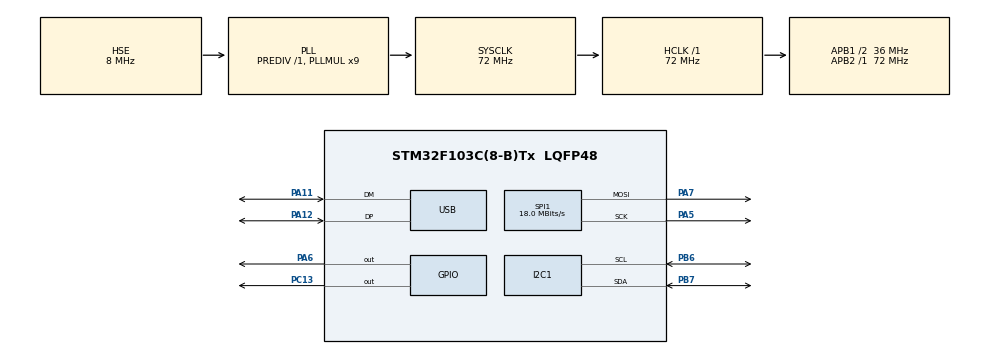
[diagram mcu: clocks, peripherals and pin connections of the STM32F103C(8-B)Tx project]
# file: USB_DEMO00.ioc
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Mcu.Family=STM32F1
Mcu.Name=STM32F103C(8-B)Tx
Mcu.Package=LQFP48
NVIC.PriorityGroup=NVIC_PRIORITYGROUP_4
NVIC.USB_LP_CAN1_RX0_IRQn=true\:0\:0\:false\:false\:true\:false\:true\:true
PA11.Mode=Device
PA11.Signal=USB_DM
PA12.Mode=Device
PA12.Signal=USB_DP
PA13.Mode=Serial_Wire
PA13.Signal=SYS_JTMS-SWDIO
PA14.Mode=Serial_Wire
PA14.Signal=SYS_JTCK-SWCLK
PA5.Mode=TX_Only_Simplex_Unidirect_Master
PA5.Signal=SPI1_SCK
PA6.Signal=GPIO_Output
PA7.Mode=TX_Only_Simplex_Unidirect_Master
PA7.Signal=SPI1_MOSI
PB6.Mode=I2C
PB6.Signal=I2C1_SCL
PB7.Mode=I2C
PB7.Signal=I2C1_SDA
PC13-TAMPER-RTC.Signal=GPIO_Output
PC14-OSC32_IN.Mode=LSE-External-Oscillator
PC14-OSC32_IN.Signal=RCC_OSC32_IN
PC15-OSC32_OUT.Mode=LSE-External-Oscillator
PC15-OSC32_OUT.Signal=RCC_OSC32_OUT
PD0-OSC_IN.Mode=HSE-External-Oscillator
PD0-OSC_IN.Signal=RCC_OSC_IN
PD1-OSC_OUT.Mode=HSE-External-Oscillator
PD1-OSC_OUT.Signal=RCC_OSC_OUT
ProjectManager.HeapSize=0x200
ProjectManager.StackSize=0x400
ProjectManager.TargetToolchain=CMake
RCC.AHBFreq_Value=72000000
RCC.APB1CLKDivider=RCC_HCLK_DIV2
RCC.APB1Freq_Value=36000000
RCC.APB1TimFreq_Value=72000000
RCC.APB2Freq_Value=72000000
RCC.APB2TimFreq_Value=72000000
RCC.HCLKFreq_Value=72000000
RCC.PLLMUL=RCC_PLL_MUL9
RCC.SYSCLKFreq_VALUE=72000000
RCC.SYSCLKSource=RCC_SYSCLKSOURCE_PLLCLK
RCC.USBFreq_Value=48000000
RCC.USBPrescaler=RCC_USBCLKSOURCE_PLL_DIV1_5
SPI1.BaudRatePrescaler=SPI_BAUDRATEPRESCALER_4
SPI1.CalculateBaudRate=18.0 MBits/s
SPI1.Direction=SPI_DIRECTION_2LINES
SPI1.Mode=SPI_MODE_MASTER
SPI1.VirtualType=VM_MASTER
USB_DEVICE.CLASS_NAME_FS=CDC
USB_DEVICE.VirtualMode=Cdc
USB_DEVICE.VirtualModeFS=Cdc_FS
VP_USB_DEVICE_VS_USB_DEVICE_CDC_FS.Mode=CDC_FS
board=custom

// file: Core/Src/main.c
/* USER CODE BEGIN Header */
/**
  ******************************************************************************
  * @file           : main.c
  * @brief          : Main program body
  ******************************************************************************
  * @attention
  *
  * Copyright (c) 2025 STMicroelectronics.
  * All rights reserved.
  *
  * This software is licensed under terms that can be found in the LICENSE file
  * in the root directory of this software component.
  * If no LICENSE file comes with this software, it is provided AS-IS.
  *
  ******************************************************************************
  */
/* USER CODE END Header */
#include "main.h"
#include "stm32f1xx_hal.h"
#include "stm32f1xx_hal_gpio.h"
#include "usb_device.h"
#include "usbd_cdc_if.h"
#include <stdio.h>   // 添加用于sprintf
#include <string.h>  // 添加用于strlen
#include <stdbool.h> // 添加用于bool类型

I2C_HandleTypeDef hi2c1;

SPI_HandleTypeDef hspi1;

/* USER CODE BEGIN PV */
uint16_t shift_register_data[1] = {0x0FF0};
/* USER CODE END PV */

void SystemClock_Config(void);
static void MX_GPIO_Init(void);
static void MX_I2C1_Init(void);
static void MX_SPI1_Init(void);

int main(void)
{

  /* MCU Configuration--------------------------------------------------------*/

  /* Reset of all peripherals, Initializes the Flash interface and the Systick. */
  HAL_Init();

  /* Configure the system clock */
  SystemClock_Config();

  /* Initialize all configured peripherals */
  MX_GPIO_Init();
  MX_I2C1_Init();
  MX_SPI1_Init();
  MX_USB_DEVICE_Init();

  /* Infinite loop */
  while (1)
  {
    if (usb_data_ready)
    {
      // 数据处理前状态输出
      char status_msg[64];
      int len = sprintf(status_msg, "Data received: Length=%lu, Data=", usb_rx_len);
      for(uint32_t i = 0; i < usb_rx_len && i < 16; i++) {
        len += sprintf(&status_msg[len], "%02X", UserRxBufferFS[i]);
      }
      sprintf(&status_msg[len], "\r\n");
      CDC_Transmit_FS((uint8_t*)status_msg, strlen(status_msg));

      // 此时 UserRxBufferFS 中有数据，长度为 usb_rx_len
      // 直接将接收到的字节作为十六进制数据处理
      uint16_t data_to_send = 0;
      bool processing_success = false;

      if(usb_rx_len == 2) { // 接收2个字节的数据，组成16位数据
          // 数据处理中状态输出
          CDC_Transmit_FS((uint8_t*)"Processing 2-byte hex data...\r\n", 30);

          // 直接将接收到的2个字节组合成16位数据，保持字节顺序（第一个字节为高字节，第二个字节为低字节）
          uint16_t raw_data = ((uint16_t)UserRxBufferFS[0] << 8) | UserRxBufferFS[1];

          // 将整个两字节数据按位倒序
          data_to_send = 0;
          for(int bit = 0; bit < 16; bit++) {
              if(raw_data & (1 << bit)) {
                  data_to_send |= (1 << (15 - bit));
              }
          }

          // 通过SPI发送16位数据 - 在16位模式下，Size参数为1（表示1个16位数据项）
          HAL_StatusTypeDef status = HAL_SPI_Transmit(&hspi1, (uint8_t*)&data_to_send, 1, 100);  // 传输1个16位数据项
          HAL_GPIO_WritePin(GPIOA, GPIO_PIN_6, GPIO_PIN_SET); /* PA6拉高 */
          HAL_Delay(1); /* 延时保持脉冲宽度 */
          HAL_GPIO_WritePin(GPIOA, GPIO_PIN_6, GPIO_PIN_RESET); /* PA6拉低 */

          if(status != HAL_OK) {
            // 如果传输失败，记录错误或重新初始化SPI
            CDC_Transmit_FS((uint8_t*)"SPI transmission failed!\r\n", 26);
            Error_Handler();
          } else {
            // SPI传输成功状态输出
            char spi_msg[64];
            sprintf(spi_msg, "SPI sent: 0x%04X\r\n", data_to_send);
            CDC_Transmit_FS((uint8_t*)spi_msg, strlen(spi_msg));

            processing_success = true;
          }
      } else {
          // 非2字节数据被忽略的状态输出
          char ignore_msg[64];
          sprintf(ignore_msg, "Data invalid: Length=%lu (expected 2)\r\n", usb_rx_len);
          CDC_Transmit_FS((uint8_t*)ignore_msg, strlen(ignore_msg));

      }
      // 数据处理后状态输出
      usb_data_ready = 0;
      HAL_Delay(10);
      if(processing_success) {
          CDC_Transmit_FS((uint8_t*)"Processing completed successfully.\r\n", 36);
      } else {
          CDC_Transmit_FS((uint8_t*)"Processing failed.\r\n", 20);
      }

      // 清除标志（注意：此处非原子操作，简单应用可接受）

      // 如果需要，可以在这里赋值给你的主逻辑变量
      // 例如：my_global_cmd = UserRxBufferFS[0];
    }

    HAL_Delay(1); // 避免死循环占满 CPU
    // HAL_GPIO_TogglePin(GPIOC, GPIO_PIN_13);
    // CDC_Transmit_FS((uint8_t *)"Hello USB!\r\n", 13);
    // HAL_Delay(500);
  }

}

void SystemClock_Config(void)
{
  RCC_OscInitTypeDef RCC_OscInitStruct = {0};
  RCC_ClkInitTypeDef RCC_ClkInitStruct = {0};
  RCC_PeriphCLKInitTypeDef PeriphClkInit = {0};

  /** Initializes the RCC Oscillators according to the specified parameters
  * in the RCC_OscInitTypeDef structure.
  */
  RCC_OscInitStruct.OscillatorType = RCC_OSCILLATORTYPE_HSE;
  RCC_OscInitStruct.HSEState = RCC_HSE_ON;
  RCC_OscInitStruct.HSEPredivValue = RCC_HSE_PREDIV_DIV1;
  RCC_OscInitStruct.HSIState = RCC_HSI_ON;
  RCC_OscInitStruct.PLL.PLLState = RCC_PLL_ON;
  RCC_OscInitStruct.PLL.PLLSource = RCC_PLLSOURCE_HSE;
  RCC_OscInitStruct.PLL.PLLMUL = RCC_PLL_MUL9;
  if (HAL_RCC_OscConfig(&RCC_OscInitStruct) != HAL_OK)
  {
    Error_Handler();
  }

  /** Initializes the CPU, AHB and APB buses clocks
  */
  RCC_ClkInitStruct.ClockType = RCC_CLOCKTYPE_HCLK|RCC_CLOCKTYPE_SYSCLK
                              |RCC_CLOCKTYPE_PCLK1|RCC_CLOCKTYPE_PCLK2;
  RCC_ClkInitStruct.SYSCLKSource = RCC_SYSCLKSOURCE_PLLCLK;
  RCC_ClkInitStruct.AHBCLKDivider = RCC_SYSCLK_DIV1;
  RCC_ClkInitStruct.APB1CLKDivider = RCC_HCLK_DIV2;
  RCC_ClkInitStruct.APB2CLKDivider = RCC_HCLK_DIV1;

  if (HAL_RCC_ClockConfig(&RCC_ClkInitStruct, FLASH_LATENCY_2) != HAL_OK)
  {
    Error_Handler();
  }
  PeriphClkInit.PeriphClockSelection = RCC_PERIPHCLK_USB;
  PeriphClkInit.UsbClockSelection = RCC_USBCLKSOURCE_PLL_DIV1_5;
  if (HAL_RCCEx_PeriphCLKConfig(&PeriphClkInit) != HAL_OK)
  {
    Error_Handler();
  }
}

static void MX_I2C1_Init(void)
{

  hi2c1.Instance = I2C1;
  hi2c1.Init.ClockSpeed = 100000;
  hi2c1.Init.DutyCycle = I2C_DUTYCYCLE_2;
  hi2c1.Init.OwnAddress1 = 0;
  hi2c1.Init.AddressingMode = I2C_ADDRESSINGMODE_7BIT;
  hi2c1.Init.DualAddressMode = I2C_DUALADDRESS_DISABLE;
  hi2c1.Init.OwnAddress2 = 0;
  hi2c1.Init.GeneralCallMode = I2C_GENERALCALL_DISABLE;
  hi2c1.Init.NoStretchMode = I2C_NOSTRETCH_DISABLE;
  if (HAL_I2C_Init(&hi2c1) != HAL_OK)
  {
    Error_Handler();
  }

}

static void MX_SPI1_Init(void)
{

  /* SPI1 parameter configuration*/
  hspi1.Instance = SPI1;
  hspi1.Init.Mode = SPI_MODE_MASTER;
  hspi1.Init.Direction = SPI_DIRECTION_2LINES;
  hspi1.Init.DataSize = SPI_DATASIZE_16BIT;
  hspi1.Init.CLKPolarity = SPI_POLARITY_LOW;
  hspi1.Init.CLKPhase = SPI_PHASE_1EDGE;
  hspi1.Init.NSS = SPI_NSS_SOFT;
  hspi1.Init.BaudRatePrescaler = SPI_BAUDRATEPRESCALER_64;
  hspi1.Init.FirstBit = SPI_FIRSTBIT_MSB;
  hspi1.Init.TIMode = SPI_TIMODE_DISABLE;
  hspi1.Init.CRCCalculation = SPI_CRCCALCULATION_DISABLE;
  hspi1.Init.CRCPolynomial = 10;
  if (HAL_SPI_Init(&hspi1) != HAL_OK)
  {
    Error_Handler();
  }

}

static void MX_GPIO_Init(void)
{
  GPIO_InitTypeDef GPIO_InitStruct = {0};

  /* GPIO Ports Clock Enable */
  __HAL_RCC_GPIOC_CLK_ENABLE();
  __HAL_RCC_GPIOD_CLK_ENABLE();
  __HAL_RCC_GPIOA_CLK_ENABLE();
  __HAL_RCC_GPIOB_CLK_ENABLE();

  /*Configure GPIO pin Output Level */
  HAL_GPIO_WritePin(GPIOC, GPIO_PIN_13, GPIO_PIN_RESET);

  /*Configure GPIO pin Output Level */
  HAL_GPIO_WritePin(GPIOA, GPIO_PIN_6, GPIO_PIN_RESET);

  /*Configure GPIO pin : PC13 */
  GPIO_InitStruct.Pin = GPIO_PIN_13;
  GPIO_InitStruct.Mode = GPIO_MODE_OUTPUT_PP;
  GPIO_InitStruct.Pull = GPIO_NOPULL;
  GPIO_InitStruct.Speed = GPIO_SPEED_FREQ_LOW;
  HAL_GPIO_Init(GPIOC, &GPIO_InitStruct);

  /*Configure GPIO pin : PA6 */
  GPIO_InitStruct.Pin = GPIO_PIN_6;
  GPIO_InitStruct.Mode = GPIO_MODE_OUTPUT_PP;
  GPIO_InitStruct.Pull = GPIO_NOPULL;
  GPIO_InitStruct.Speed = GPIO_SPEED_FREQ_LOW;
  HAL_GPIO_Init(GPIOA, &GPIO_InitStruct);

}

void Error_Handler(void)
{
  /* USER CODE BEGIN Error_Handler_Debug */
  /* User can add his own implementation to report the HAL error return state */
  __disable_irq();
  while (1)
  {
    HAL_GPIO_TogglePin(GPIOC, GPIO_PIN_13);
    HAL_Delay(500);
  }
  /* USER CODE END Error_Handler_Debug */
}
